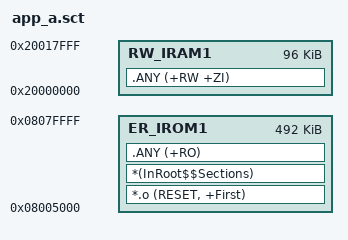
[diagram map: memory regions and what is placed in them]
; ============================================================================
; GD32F303VGT6  App Slot A  分散加载文件 (Keil MDK / armlink)
; Flash: 0x08005000, 492 KiB (0x7B000)   SRAM: 0x20000000, 96 KiB
; 注意: 向量表偏移必须在 App main() 里用
;       nvic_vector_table_set(NVIC_VECTTAB_FLASH, 0x00005000) 设置, 工程已包含。
; ============================================================================
LR_IROM1 0x08005000 0x0007B000  {
  ER_IROM1 0x08005000 0x0007B000  {
    *.o (RESET, +First)
    *(InRoot$$Sections)
    .ANY (+RO)
  }
  RW_IRAM1 0x20000000 0x00018000  {
    .ANY (+RW +ZI)
  }
}
